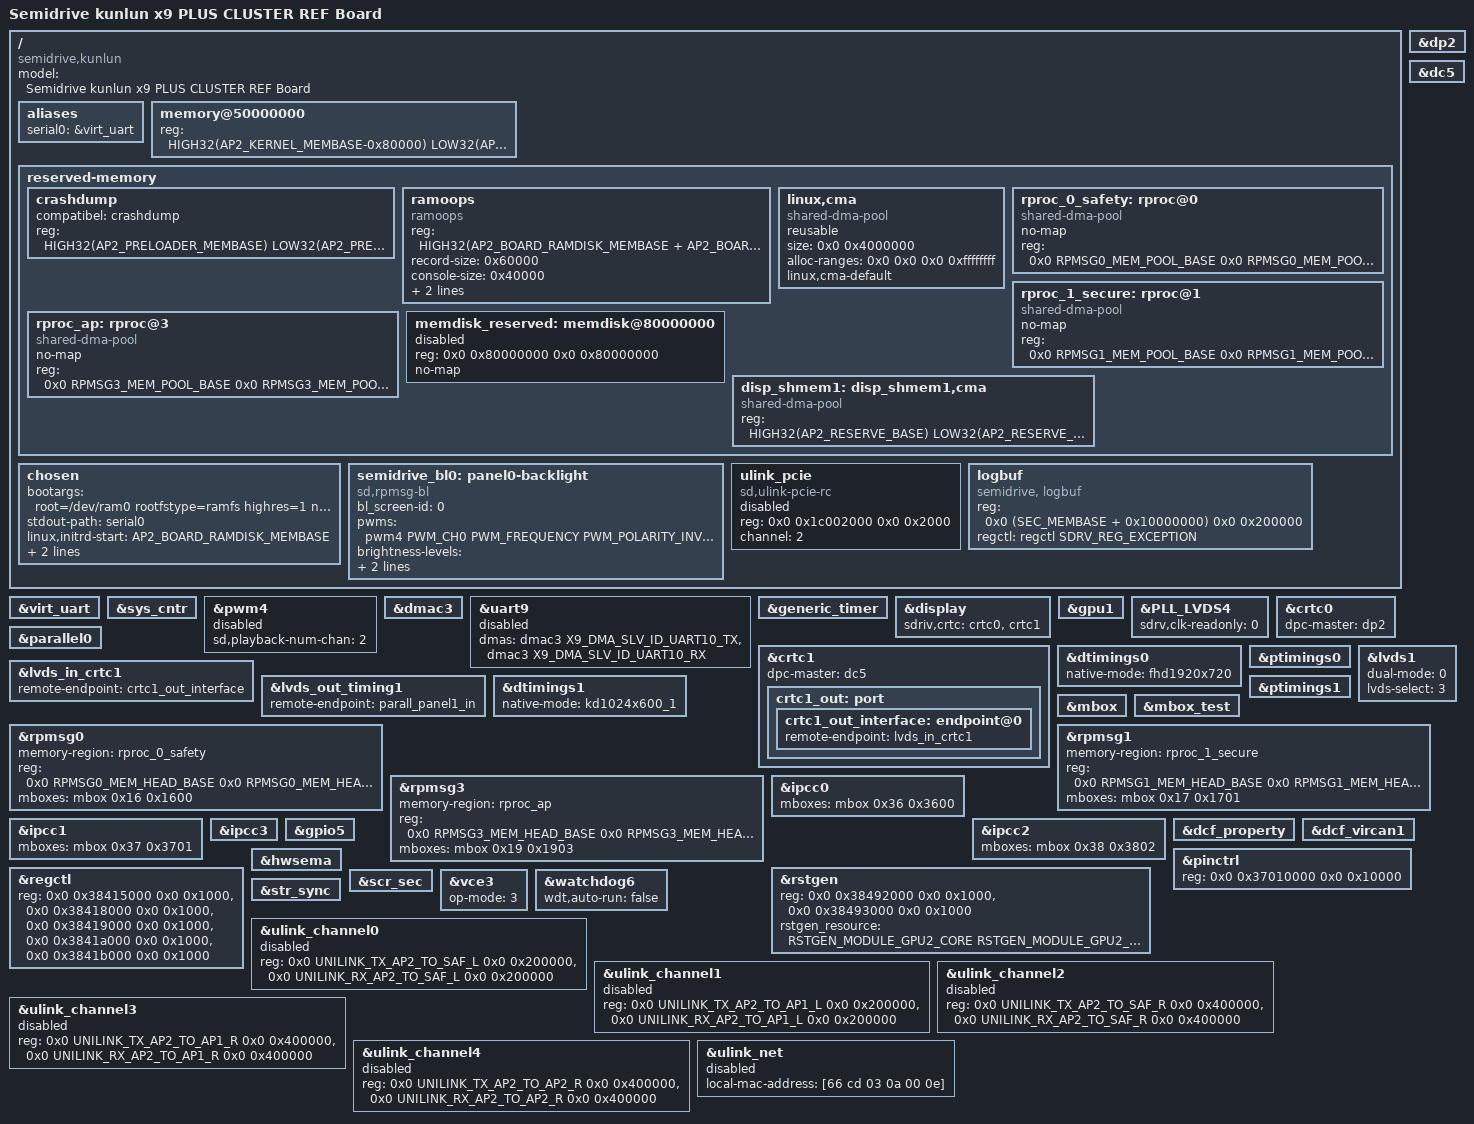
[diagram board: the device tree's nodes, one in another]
/*
 * Semidrive kunlun platform DTS file
 *
 * Copyright (C) 2019, Semidrive  Communications Inc.
 *
 * This file is licensed under a dual GPLv2 or X11 license.
 */

/dts-v1/;

#include "x9_ultra_cluster_a.dtsi"
#include "x9_ultra_ref_cluster-clk-ctrl_a.dtsi"
#include "lcd-timings.dtsi"
#include <dt-bindings/pinctrl/pins-sdx9.h>
#include <dt-bindings/memmap/x9_ultra/projects/ms_serdes/side_a/image_cfg.h>
#include <dt-bindings/rpmsg/sd,x9u-ap2.h>
#include <dt-bindings/backlight/sdrv_backlight.h>
#include <dt-bindings/soc/sdrv-unilink-x9u.h>
#include <dt-bindings/memmap/mem_share.h>

/ {
	model = "Semidrive kunlun x9 PLUS CLUSTER REF Board";

	compatible = "semidrive,kunlun";

	aliases {
		serial0 = &virt_uart;
	};

	memory@50000000 {
		device_type = "memory";
		reg = <HIGH32(AP2_KERNEL_MEMBASE-0x80000) LOW32(AP2_KERNEL_MEMBASE-0x80000) HIGH32(AP2_KERNEL_MEMSIZE) LOW32(AP2_KERNEL_MEMSIZE) \
			HIGH32(AP2_RESERVE_BASE) LOW32(AP2_RESERVE_BASE) HIGH32(AP2_RESERVE_SIZE) LOW32(AP2_RESERVE_SIZE)>;
	};

	reserved-memory {
		#address-cells = <2>;
		#size-cells = <2>;
		ranges;

		crashdump {
			/* reserve preloader mem for crashdump */
			compatibel = "crashdump";
			reg = <HIGH32(AP2_PRELOADER_MEMBASE) LOW32(AP2_PRELOADER_MEMBASE) 0 AP2_PRELOADER_MEMSIZE>;
		};

		ramoops {
			compatible = "ramoops";
			reg = <HIGH32(AP2_BOARD_RAMDISK_MEMBASE + AP2_BOARD_RAMDISK_MEMSIZE + 0x1000000)
				LOW32(AP2_BOARD_RAMDISK_MEMBASE + AP2_BOARD_RAMDISK_MEMSIZE + 0x1000000) 0x0 0x100000>;
			record-size = <0x60000>;
			console-size = <0x40000>;
			ftrace-size = <0x20000>;
			pmsg-size = <0x40000>;
		};

		/* Default Common CMA Pool */
		/* QUIRK: Must be kept in the lower 4096 MiBs of DRAM banks for VE */
		linux,cma {
			compatible = "shared-dma-pool";
			reusable;
			size = <0x0 0x4000000>; /* 64MB */
			/* 4GB maximum in case of 32-bit only capable devices */
			alloc-ranges = <0x0 0x0 0x0 0xffffffff>;
			linux,cma-default;
		};

		rproc_0_safety: rproc@0 {
			compatible = "shared-dma-pool";
			no-map;
			reg = <0x0 RPMSG0_MEM_POOL_BASE 0x0 RPMSG0_MEM_POOL_SIZE>;
		};

		rproc_1_secure: rproc@1 {
			compatible = "shared-dma-pool";
			no-map;
			reg = <0x0 RPMSG1_MEM_POOL_BASE 0x0 RPMSG1_MEM_POOL_SIZE>;
		};

		rproc_ap: rproc@3 {
			compatible = "shared-dma-pool";
			no-map;
			reg = <0x0 RPMSG3_MEM_POOL_BASE 0x0 RPMSG3_MEM_POOL_SIZE>;
		};

		memdisk_reserved: memdisk@80000000 {
			reg = <0x0 0x80000000 0x0 0x80000000>;
			no-map;
			status = "disabled";
		};

		disp_shmem1: disp_shmem1,cma {
			compatible = "shared-dma-pool";
			reg = <HIGH32(AP2_RESERVE_BASE) LOW32(AP2_RESERVE_BASE) HIGH32(AP2_RESERVE_SIZE) LOW32(AP2_RESERVE_SIZE)>;
			status = "okay";
		};
	};

	chosen {
		bootargs = "root=/dev/ram0 rootfstype=ramfs highres=1 nr_cpus=1 loglevel=4 console=ttyV0 fbcon=map:1 androidboot.mode=normal androidboot.selinux=permissive androidboot.debuggable=0 androidboot.dm_verity=disable psplash=false init=/init";
		stdout-path = "serial0";
		linux,initrd-start = <AP2_BOARD_RAMDISK_MEMBASE>;
		linux,initrd-end   = <(AP2_BOARD_RAMDISK_MEMBASE + AP2_BOARD_RAMDISK_MEMSIZE)>;/* 64MB */
	};

	semidrive_bl0: panel0-backlight {
		compatible = "sd,rpmsg-bl"; /*"sd,rpmsg-bl" for rpmsg; "pwm-backlight" for native*/
		bl_screen-id = /bits/ 32 <0>;
		pwms = <&pwm4 PWM_CH0 PWM_FREQUENCY PWM_POLARITY_INVERSED>;
		brightness-levels = <0 1 2 3 4 5 6 7 8 9 10 11 12 13 14 15 16
							 17 18 19 20 21 22 23 24 25 26 27 28 29 30
							 31 32 33 34 35 36 37 38 39 40 41 42 43 44
							 45 46 47 48 49 50 51 52 53 54 55 56 57 58
							 59 60 61 62 63 64 65 66 67 68 69 70 71 72
							 73 74 75 76 77 78 79 80 81 82 83 84 85 86
							 87 88 89 90 91 92 93 94 95 96 97 98 99 100>;
		default-brightness-level = <70>;
		status = "okay";
	};

	ulink_pcie: ulink_pcie {
		compatible = "sd,ulink-pcie-rc";
		reg = <0x0 0x1c002000 0x0 0x2000>;
		channel = <2>;
		status = "disabled";
	};

	logbuf {
		compatible = "semidrive, logbuf";
		reg = <0x0 (SEC_MEMBASE + 0x10000000) 0x0 0x200000>;
		regctl = <&regctl SDRV_REG_EXCEPTION>;
		status = "okay";
	};
};

&virt_uart {
	status = "okay";
};

&sys_cntr {
	status = "okay";
};

&pwm4 {
	sd,playback-num-chan = <2>;
	#pwm-cells = <3>;
	status = "disabled";
};

&dmac3 {
	status = "okay";
};

&uart9 {
	dmas = <&dmac3 X9_DMA_SLV_ID_UART10_TX>, <&dmac3 X9_DMA_SLV_ID_UART10_RX>;
	dma-names = "tx", "rx";
	status = "disabled";
};

&generic_timer {
	status = "okay";
};

&display {
	sdriv,crtc = <&crtc0 &crtc1>;
	status = "okay";
};

&gpu1 {
	status = "okay";
};
&dp2 {
	status = "okay";
};

&dc5 {
	status = "okay";
};

&PLL_LVDS4 {
	sdrv,clk-readonly = <0>;
	status = "okay";
};

&crtc0 {
	dpc-master = <&dp2>;
	status = "okay";
};

&crtc1 {
	dpc-master = <&dc5>;
	status = "okay";

	crtc1_out: port {
		crtc1_out_interface: endpoint@0 {
			remote-endpoint = <&lvds_in_crtc1>;
		};
	};
};

&parallel0 {
	status = "okay";
};

&dtimings0 {
	native-mode = <&fhd1920x720>;
};

&ptimings0 {
	status = "okay";
};


&lvds1 {
	dual-mode = <0>;
	lvds-select = <3>;
	status = "okay";
};

&lvds_in_crtc1 {
	remote-endpoint = <&crtc1_out_interface>;
};

&lvds_out_timing1 {
	remote-endpoint = <&parall_panel1_in>;
};

&dtimings1 {
	native-mode = <&kd1024x600_1>;
};

&ptimings1 {
	status = "okay";
};

&mbox {
	status = "okay";
};

&mbox_test {
	status = "okay";
};

&rpmsg0 {
	memory-region = <&rproc_0_safety>;
	reg = <0x0 RPMSG0_MEM_HEAD_BASE 0x0 RPMSG0_MEM_HEAD_SIZE>;
	mboxes = <&mbox 0x16 0x1600>;
	status = "okay";
};

&rpmsg1 {
	memory-region = <&rproc_1_secure>;
	reg = <0x0 RPMSG1_MEM_HEAD_BASE 0x0 RPMSG1_MEM_HEAD_SIZE>;
	mboxes = <&mbox 0x17 0x1701>;
	status = "okay";
};

&rpmsg3 {
	memory-region = <&rproc_ap>;
	reg = <0x0 RPMSG3_MEM_HEAD_BASE 0x0 RPMSG3_MEM_HEAD_SIZE>;
	mboxes = <&mbox 0x19 0x1903>;
	status = "okay";
};

&ipcc0 {
	mboxes = <&mbox 0x36 0x3600>;
	status = "okay";
};

&ipcc1 {
	mboxes = <&mbox 0x37 0x3701>;
	status = "okay";
};

&ipcc2 {
	mboxes = <&mbox 0x38 0x3802>;
	status = "okay";
};

&ipcc3 {
	status = "okay";
};

&dcf_property {
	status = "okay";
};

&dcf_vircan1 {
	status = "okay";
};

&pinctrl {
	reg = <0x0 0x37010000 0x0 0x10000>;
};

&gpio5 {
	status = "okay";
};

&rstgen {
	reg = <0x0 0x38492000 0x0 0x1000>,	/* gpu2 core */
		<0x0 0x38493000 0x0 0x1000>;	/* gpu2 ss */

	rstgen_resource = <
		RSTGEN_MODULE_GPU2_CORE
		RSTGEN_MODULE_GPU2_SS

	>;
	status = "okay";
};

&regctl {
	reg = <0x0 0x38415000 0x0 0x1000>,
		<0x0 0x38418000 0x0 0x1000>,
		<0x0 0x38419000 0x0 0x1000>,
		<0x0 0x3841a000 0x0 0x1000>,
		<0x0 0x3841b000 0x0 0x1000>;
	reg-names = "SDRV_REG_REMAP",
			"SDRV_REG_BOOTREASON",
			"SDRV_REG_HWID",
			"SDRV_REG_STATUS",
			"SDRV_REG_EXCEPTION";
	status = "okay";
};

&hwsema {
        status = "okay";
};

&scr_sec {
        status = "okay";
};

&vce3 {
   /*
 	* op-mode options:
 	* bit 0: rng enable(1) or disable(0)
 	* bit 1: ce enable(1) or disable(0)
 	*/
 	op-mode = <3>;
	status = "okay";
};

&watchdog6 {
	wdt,auto-run = "false";
	status = "okay";
};

&str_sync {
	status = "okay";
};

&ulink_channel0 {
	reg = <0x0 UNILINK_TX_AP2_TO_SAF_L 0x0 0x200000>,
		<0x0 UNILINK_RX_AP2_TO_SAF_L 0x0 0x200000>;
	status = "disabled";
};

&ulink_channel1 {
	reg = <0x0 UNILINK_TX_AP2_TO_AP1_L 0x0 0x200000>,
		<0x0 UNILINK_RX_AP2_TO_AP1_L 0x0 0x200000>;
	status = "disabled";
};

&ulink_channel2 {
	reg = <0x0 UNILINK_TX_AP2_TO_SAF_R 0x0 0x400000>,
		<0x0 UNILINK_RX_AP2_TO_SAF_R 0x0 0x400000>;
	status = "disabled";
};

&ulink_channel3 {
	reg = <0x0 UNILINK_TX_AP2_TO_AP1_R 0x0 0x400000>,
		<0x0 UNILINK_RX_AP2_TO_AP1_R 0x0 0x400000>;
	status = "disabled";
};
&ulink_channel4 {
	reg = <0x0 UNILINK_TX_AP2_TO_AP2_R 0x0 0x400000>,
		<0x0 UNILINK_RX_AP2_TO_AP2_R 0x0 0x400000>;
	status = "disabled";
};

&ulink_net {
	local-mac-address = [66 cd 03 0a 00 0e];
	status = "disabled";
};
